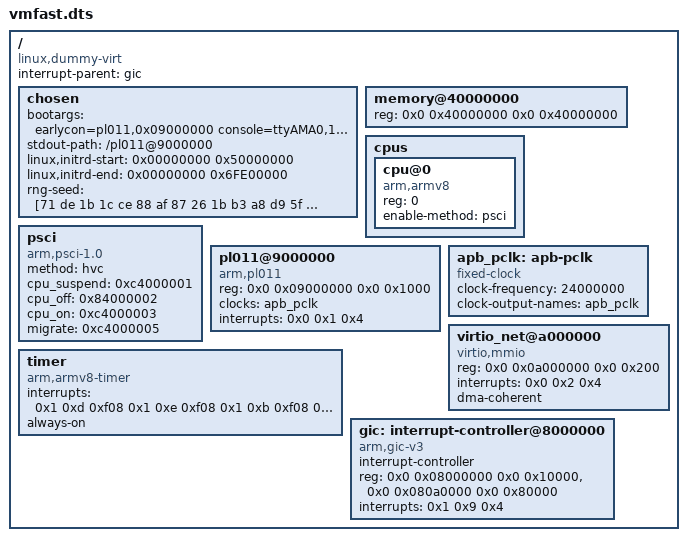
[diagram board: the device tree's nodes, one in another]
/dts-v1/;

/ {
    #address-cells = <2>;
    #size-cells = <2>;
    compatible = "linux,dummy-virt";
    interrupt-parent = <&gic>;

    chosen {
        // Earlycon writes to PL011 at 0x09000000 *before* the kernel
        // initializes any drivers, so we don't need a working GIC to
        // see printk.
        bootargs = "earlycon=pl011,0x09000000 console=ttyAMA0,115200 panic=-1 loglevel=8 rdinit=/init";
        stdout-path = "/pl011@9000000";
        // initrd populated at vmfast-linux startup. The cpio is parsed
        // up to its TRAILER!!! entry, so the end-of-region figure here
        // just has to be a safe upper bound — set near the top of RAM
        // so the ~200 MB cpio (with bundled Node.js) fits comfortably.
        linux,initrd-start = <0x00000000 0x50000000>;
        linux,initrd-end   = <0x00000000 0x6FE00000>;     // up to ~510 MB

        // Seed the kernel CRNG at boot. Without this the pool stays
        // unseeded for ~minutes of guest time (no virtio-rng, no
        // hardware entropy from a single-vCPU paravirt guest), so the
        // first getrandom()/V8 init / openssl init inside the guest
        // blocks for a very long time after restore. With rng-seed
        // present, random_init() credits these bytes as initial entropy
        // and the CRNG is "init done" before /init runs — every
        // restored VM gets immediate, non-blocking randomness.
        //
        // NB: every restored VM mmaps the same snapshot.ram, so the
        // post-boot pool state is identical across VMs regardless of
        // this seed. Demoware caveat, not a production secret.
        rng-seed = [71 de 1b 1c ce 88 af 87 26 1b b3 a8 d9 5f 0a e6
                    fb d9 73 13 99 ff ba 04 fa 4d 39 d9 2c 81 db 20
                    7f cb c4 d4 b0 3a 7e ce 05 5c 2f 51 d9 b0 2a 6f
                    cf 9b 3f 23 5b 6f b1 19 05 4d 9f 0f 22 3c 1e 58];
    };

    memory@40000000 {
        device_type = "memory";
        // 1 GiB — needed so the kernel can extract the ~200 MB cpio
        // (kernel + initrd region + growing tmpfs) without OOMing
        // partway through.
        reg = <0x0 0x40000000 0x0 0x40000000>;
    };

    cpus {
        #address-cells = <1>;
        #size-cells = <0>;

        cpu@0 {
            device_type = "cpu";
            compatible = "arm,armv8";
            reg = <0>;
            enable-method = "psci";
        };
    };

    psci {
        compatible = "arm,psci-1.0", "arm,psci-0.2", "arm,psci";
        method = "hvc";
        cpu_suspend = <0xc4000001>;
        cpu_off     = <0x84000002>;
        cpu_on      = <0xc4000003>;
        migrate     = <0xc4000005>;
    };

    pl011@9000000 {
        compatible = "arm,pl011", "arm,primecell";
        reg = <0x0 0x09000000 0x0 0x1000>;
        clocks = <&apb_pclk>;
        clock-names = "apb_pclk";
        interrupts = <0x0 0x1 0x4>;
        status = "okay";
    };

    apb_pclk: apb-pclk {
        compatible = "fixed-clock";
        #clock-cells = <0>;
        clock-frequency = <24000000>;
        clock-output-names = "apb_pclk";
    };

    // Paravirtual NIC. The stock Ubuntu kernel has virtio_mmio and
    // virtio_net built in (visible in /sys/bus/platform/drivers and
    // /sys/bus/virtio/drivers), so declaring this node is enough for
    // the kernel to probe a virtio-net device and create eth0 — no
    // modules. The VMM emulates the device (modern virtio-mmio v2) and
    // bridges frames to a userspace libslirp NAT on the host.
    //   reg:        0x0a000000, 0x200 bytes of MMIO registers
    //   interrupts: SPI 2 → INTID 34 (PL011 is SPI 1 → 33)
    //   dma-coherent: guest physical == host's mmap view, no IOMMU,
    //                 no bounce buffers / cache maintenance needed.
    virtio_net@a000000 {
        compatible = "virtio,mmio";
        reg = <0x0 0x0a000000 0x0 0x200>;
        interrupts = <0x0 0x2 0x4>;
        dma-coherent;
    };

    timer {
        compatible = "arm,armv8-timer";
        interrupts = <0x1 0xd 0xf08
                      0x1 0xe 0xf08
                      0x1 0xb 0xf08
                      0x1 0xa 0xf08>;
        always-on;
    };

    // Minimal GICv3 stub. We don't emulate it functionally, but Linux
    // panics during init if no interrupt controller is described.
    // Earlycon prints fire before the kernel touches the GIC, so we
    // expect to see banner output without trapping any GIC MMIO yet.
    gic: interrupt-controller@8000000 {
        compatible = "arm,gic-v3";
        #interrupt-cells = <3>;
        #address-cells = <2>;
        #size-cells = <2>;
        interrupt-controller;
        reg = <0x0 0x08000000 0x0 0x10000>,   // GICD
              <0x0 0x080a0000 0x0 0x80000>;   // GICR (sized for 8 redists)
        interrupts = <0x1 0x9 0x4>;
    };
};
